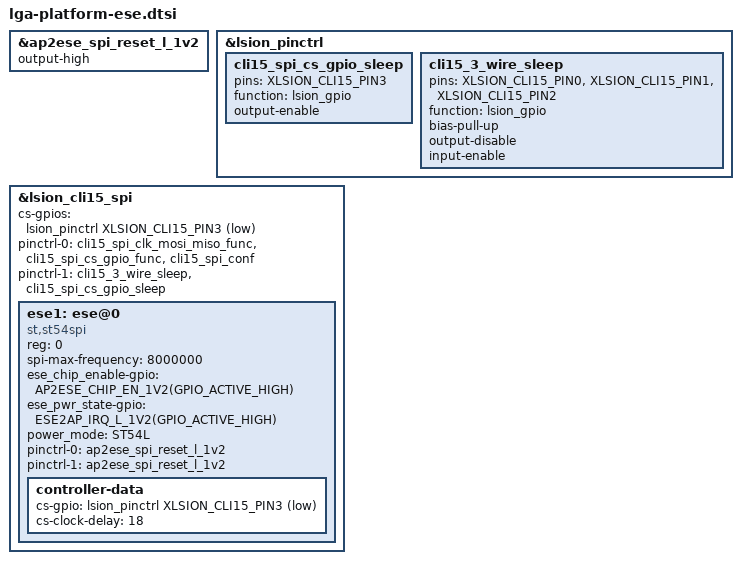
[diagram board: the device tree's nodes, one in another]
// SPDX-License-Identifier: GPL-2.0-only
/*
 * eSE device tree entries specific to the lga paltform
 *
 * Copyright 2024 Google LLC.
 *
 */

#include <dt-bindings/gpio/gpio.h>

&ap2ese_spi_reset_l_1v2 {
	output-high;
};

&lsion_pinctrl {
	cli15_spi_cs_gpio_sleep: cli15_spi_cs_gpio_sleep {
		pins = "XLSION_CLI15_PIN3";
		function = "lsion_gpio";
		output-enable;
	};
	cli15_3_wire_sleep: cli15_3_wire_sleep {
		pins =  "XLSION_CLI15_PIN0",
		"XLSION_CLI15_PIN1",
		"XLSION_CLI15_PIN2";
		function = "lsion_gpio";
		bias-pull-up;
		output-disable;
		input-enable;
	};
};


&lsion_cli15_spi {
	#address-cells = <1>;
	#size-cells = <0>;
	status = "okay";
	cs-gpios = <&lsion_pinctrl XLSION_CLI15_PIN3 GPIO_ACTIVE_LOW>;
	pinctrl-0 = <&cli15_spi_clk_mosi_miso_func>, <&cli15_spi_cs_gpio_func>, <&cli15_spi_conf>;
	pinctrl-1 = <&cli15_3_wire_sleep>, <&cli15_spi_cs_gpio_sleep>;
	ese1: ese@0 {
		compatible = "st,st54spi";
		reg = <0>;
		spi-max-frequency = <8000000>;
		ese_chip_enable-gpio = <AP2ESE_CHIP_EN_1V2(GPIO_ACTIVE_HIGH)>;
		ese_pwr_state-gpio = <ESE2AP_IRQ_L_1V2(GPIO_ACTIVE_HIGH)>;
		power_mode = "ST54L";
		pinctrl-names = "default", "func";
		pinctrl-0 = <&ap2ese_spi_reset_l_1v2>;
		pinctrl-1 = <&ap2ese_spi_reset_l_1v2>;
		controller-data {
			cs-gpio = <&lsion_pinctrl XLSION_CLI15_PIN3 GPIO_ACTIVE_LOW>;
			cs-clock-delay = <18>;
		};
	};
};

